AUTOSAR XML (schema 4-0-3)
package /ComponentTypes
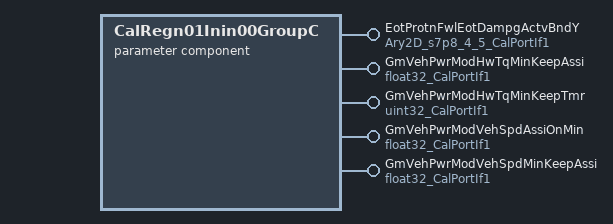
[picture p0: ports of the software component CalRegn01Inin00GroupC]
  parameter sw component type CalRegn01Inin00GroupC
    5 x provide port:
      EotProtnFwlEotDampgActvBndY: parameter-provide-com-spec{init-value=[5 x 2253, 5 x 2253, 5 x 2253, 5 x 2253], parameter=Ary2D}, provided-interface=Ary2D_s7p8_4_5_CalPortIf1
      GmVehPwrModHwTqMinKeepAssi: parameter-provide-com-spec{init-value=0.8, parameter=Val}, provided-interface=float32_CalPortIf1
      GmVehPwrModHwTqMinKeepTmr: parameter-provide-com-spec{init-value=10, parameter=Val}, provided-interface=uint32_CalPortIf1
      GmVehPwrModVehSpdAssiOnMin: parameter-provide-com-spec{init-value=0.1, parameter=Val}, provided-interface=float32_CalPortIf1
      GmVehPwrModVehSpdMinKeepAssi: parameter-provide-com-spec{init-value=3, parameter=Val}, provided-interface=float32_CalPortIf1
